AUTOSAR XML (schema 4-2-2)
package /Components
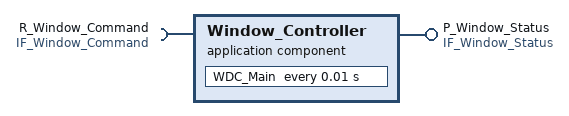
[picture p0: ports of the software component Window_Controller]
  application sw component type Window_Controller
    provide port P_Window_Status: provided-interface=IF_Window_Status
    require port R_Window_Command: required-interface=IF_Window_Command
    behavior Window_Controller_InternalBehavior
      data received event WDC_WindowCmd_Received: start-on-event=WDC_Main
      init event WDC_Init_Event: start-on-event=WDC_Main
      timing event WDC_10ms_Event: start-on-event=WDC_Main, period=0.01
      runnable WDC_Main
        data-receive-point-by-arguments:
          access WDC_VA_Read_WindowCmd: accessed-variable=R_Window_Command.window_cmd
        data-send-points:
          access WDC_VA_Write_WindowStatus: accessed-variable=P_Window_Status.window_status
